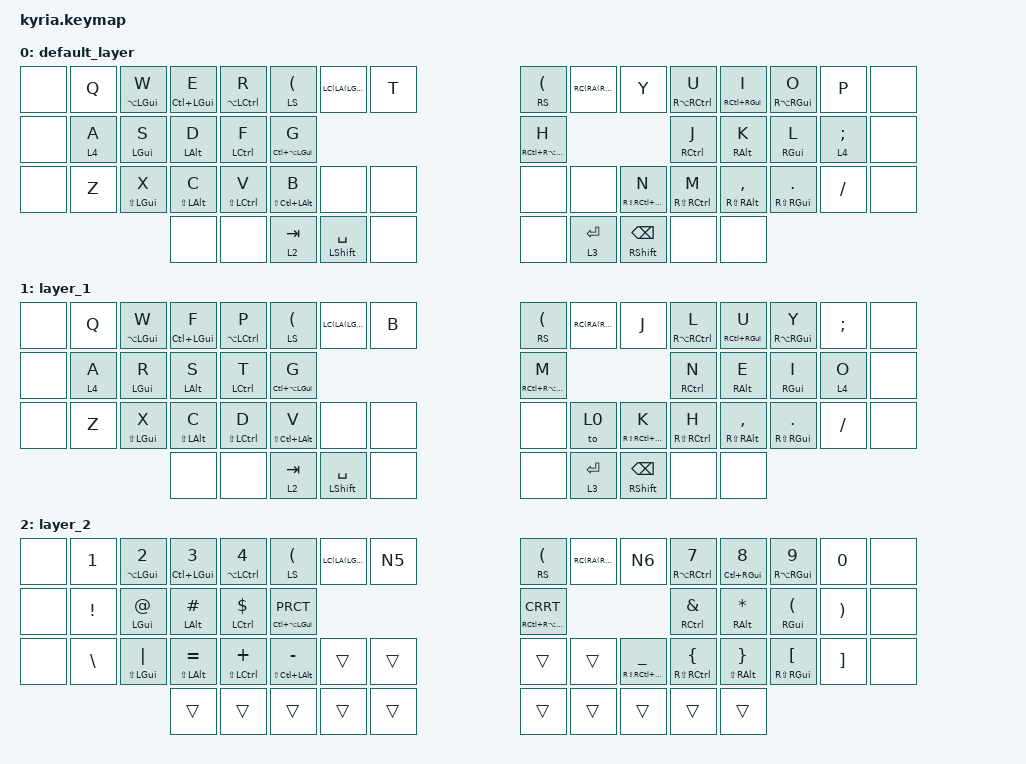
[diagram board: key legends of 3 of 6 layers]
/*
 * Copyright (c) 2020 The ZMK Contributors
 *
 * SPDX-License-Identifier: MIT
 */

#include <behaviors.dtsi>
#include <dt-bindings/zmk/keys.h>
#include <dt-bindings/zmk/outputs.h>
#include <dt-bindings/zmk/bt.h>

/ {
    behaviors {
        hm: homerow_mods {
            compatible = "zmk,behavior-hold-tap";
            label = "HOMEROW_MODS";
            #binding-cells = <2>;
            tapping-term-ms = <300>;
            quick-tap-ms = <0>;
            flavor = "tap-preferred";
            bindings = <&kp>, <&kp>;
        };
        tm: thumb_mods {
            compatible = "zmk,behavior-hold-tap";
            label = "THUMB_MODS";
            #binding-cells = <2>;
            tapping-term-ms = <200>;    // <---[[moderate duration]]
            quick-tap-ms = <0>;
            flavor = "hold-preferred";
            bindings = <&kp>, <&kp>;
        };
    };

    keymap {
        compatible = "zmk,keymap";

        default_layer {
// ---------------------------------------------------------------------------------------------------------------------------------
// Hold keys: (mods are symetrical)
// |     |     | A-G | C-G | C-A |SCA-G|                          |     |     |     |     |     |     |
// |     | L4  |  G  |  A  |  C  | CAG |                          |     |     |     |     |     |     |
// |     |     | S-G | S-A | S-C | SCA |     |     |~~|     |     |     |     |     |     |     |     |
//                   |     |     | L2  | Shf |     |~~|     | L3  | Shf |     |     |     
// ---------------------------------------------------------------------------------------------------------------------------------
// |     |  Q  |  W  |  E  |  R  |  T  |                          |  Y  |  U  |  I  |  O  |  P  |     |
// |     |  A  |  S  |  D  |  F  |  G  |                          |  H  |  J  |  K  |  L  |  ;  |     |
// |     |  Z  |  X  |  C  |  V  |  B  |     |     |~~| L1  |     |  N  |  M  |  ,  |  .  |  /  |     |
//                   |     |     | TAB | SPC |     |~~|     | RET | BKS |     |     |
            bindings = <
    &none &kp Q   &hm LA(LGUI) W &hm LC(LGUI) E &hm LA(LCTRL) R &hm LS(LC(LA(LGUI))) T                                           &hm RS(RC(RA(RGUI))) Y &hm RA(RCTRL) U &hm RC(RGUI) I     &hm RA(RGUI) O   &kp P      &none
    &none &lt 4 A &hm    LGUI  S &hm    LALT  D &hm    LCTRL  F &hm LC(LA(LGUI)) G                                               &hm RC(RA(RGUI)) H     &hm    RCTRL  J &hm    RALT  K     &hm    RGUI  L   &lt 4 SEMI &none
    &none &kp Z   &hm LS(LGUI) X &hm LS(LALT) C &hm LS(LCTRL) V &hm LS(LC(LALT)) B     &none           &none     &none &none     &hm RS(RC(RALT)) N     &hm RS(RCTRL) M &hm RS(RALT) COMMA &hm RS(RGUI) DOT &kp FSLH   &none
                                 &none          &none           &lt 2 TAB              &tm LSHFT SPACE &none     &none &lt 3 RET &tm RSHFT BKSP         &none           &none
            >;

            sensor-bindings = <&inc_dec_kp C_VOL_DN C_VOL_UP &inc_dec_kp LEFT RIGHT>;
        };

        layer_1 {
// ---------------------------------------------------------------------------------------------------------------------------------
// Hold keys: Same as above
// ---------------------------------------------------------------------------------------------------------------------------------
// Tap keys for Colemak
// |     |  Q  |  W  |  F  |  P  |  B  |                          |  J  |  L  |  U  |  Y  |  ;  |     |
// |     |  A  |  R  |  S  |  T  |  G  |                          |  M  |  N  |  E  |  I  |  O  |     |
// |     |  Z  |  X  |  C  |  D  |  V  |     |     |~~|     | L0  |  K  |  H  |  ,  |  .  |  /  |     |
//                   |     |     | TAB | SPC |     |~~|     | RET | BKS |     |     |
            bindings = <
    &none &kp Q   &hm LA(LGUI) W &hm LC(LGUI) F &hm LA(LCTRL) P &hm LS(LC(LA(LGUI))) B                                           &hm RS(RC(RA(RGUI))) J &hm RA(RCTRL) L &hm RC(RGUI) U     &hm RA(RGUI) Y   &kp SEMI  &none
    &none &lt 4 A &hm    LGUI  R &hm    LALT  S &hm    LCTRL  T &hm LC(LA(LGUI)) G                                               &hm RC(RA(RGUI)) M     &hm    RCTRL  N &hm    RALT  E     &hm    RGUI  I   &lt 4 O   &none
    &none &kp Z   &hm LS(LGUI) X &hm LS(LALT) C &hm LS(LCTRL) D &hm LS(LC(LALT)) V     &none           &none     &none &to 0     &hm RS(RC(RALT)) K     &hm RS(RCTRL) H &hm RS(RALT) COMMA &hm RS(RGUI) DOT &kp FSLH  &none
                                 &none          &none           &lt 2 TAB              &tm LSHFT SPACE &none     &none &lt 3 RET &tm RSHFT BKSP         &none           &none
            >;

            sensor-bindings = <&inc_dec_kp C_VOL_DN C_VOL_UP &inc_dec_kp LEFT RIGHT>;
        };

        layer_2 {
// ---------------------------------------------------------------------------------------------------------------------------------
// |     |  1  |  2  |  3  |  4  |  5  |                           |  6  |  7  |  8  |  9  |  0   |     |
// |     |  !  |  @  |  #  |  $  |  %  |                           |  ^  |  &  |  *  |  (  |  )   |     |
// |     |  \  |  |  |  =  |  +  |  -  |     |     |~~|     |      |  _  |  {  |  }  |  [  |  ]   |     |
//                   |     |     |     |     |     |~~|     |      |     |     |     |
            bindings = <
    &none &kp N1   &hm LA(LGUI) N2   &hm LC(LGUI) N3   &hm LA(LCTRL) N4   &hm LS(LC(LA(LGUI))) N5                                &hm RS(RC(RA(RGUI))) N6 &hm RA(RCTRL) N7   &hm LC(RGUI) N8   &hm RA(RGUI) N9   &kp N0   &none
    &none &kp EXCL &hm    LGUI  AT   &hm    LALT  HASH &hm    LCTRL  DLLR &hm LC(LA(LGUI)) PRCT                                  &hm RC(RA(RGUI)) CRRT   &hm    RCTRL  AMPS &hm    RALT  STAR &hm    RGUI  LPAR &kp RPAR &none
    &none &kp BSLH &hm LS(LGUI) PIPE &hm LS(LALT) EQL  &hm LS(LCTRL) PLUS &hm LS(LC(LALT)) MINUS  &trans &trans    &trans &trans &hm RS(RC(RALT)) UNDER  &hm RS(RCTRL) LBRC &hm LS(RALT) RBRC &hm RS(RGUI) LBKT &kp RBKT &none
                                     &trans            &trans             &trans                  &trans &trans    &trans &trans &trans                  &trans             &trans
            >;

            sensor-bindings = <&inc_dec_kp C_PREV C_NEXT &inc_dec_kp PG_UP PG_DN>;
        };

        layer_3 {
// QWERT is going to layer 0 for qerty
// COLMK is going to layer 1 for colemak
// 
// Note: Layer 3 doesn't have homerow mods on the right hand side, and some home row mods combos aren't available on the left.
//       This is intentional, at least for the movement and bks/del keys, this way they can be repeated by holding them.
// ---------------------------------------------------------------------------------------------------------------------------------
// |     |QWERT|COLMK|     |     |BT/USB|                         |     |  ~  | BKS | DEL |  `  |     |
// |     |     |     |     |     |     |                          |LEFT |DOWN | UP  |RIGHT|  '  |     |
// |     |     |     |     |     |     |     |     |  |     |     |HOME |P-DW |P-UP | END |  "  |     |
//                   |     |     |     |     |     |  |     |     |     |     |     |
            bindings = <
    &trans &to 0  &to 1  &trans &trans &out OUT_TOG                                &none    &kp TILD  &kp BKSP  &kp DEL   &kp GRAV &trans
    &trans &trans &trans &trans &trans &trans                                      &kp LEFT &kp DOWN  &kp UP    &kp RIGHT &kp SQT  &trans
    &trans &trans &trans &trans &trans &trans       &trans &trans    &trans &trans &kp HOME &kp PGDN  &kp PGUP  &kp END   &kp DQT  &trans
                         &trans &trans &trans       &trans &trans    &trans &trans &trans   &trans    &trans
            >;

            sensor-bindings = <&inc_dec_kp LC(LS(TAB)) LC(TAB) &inc_dec_kp PG_UP PG_DN>;
        };

        layer_4 {
// Note: Layer 4 doesn't have home row mods, but technically they could be added.
// ---------------------------------------------------------------------------------------------------------------------------------
// |     | F1  | F2  | F3  | F4  | F5  |                          | F6  | F7  | F8  | F9  | F10 |     |
// |     | FWD |NEXT |PLAY |VOL-U|MUTE |                          | F11 | F12 |     |     |     |     |
// |     | BWD |PREV |PAUSE|VOL-D|     |     |     |~~|     |     |     |     |     |     |     |     |
//                   |     |     |     |     | ESC |~~|     |     |     |     |     |
            bindings = <    
    &trans &kp F1   &kp F2     &kp F3      &kp F4   &kp F5                                     &kp F6  &kp F7  &kp F8 &kp F9 &kp F10 &trans
    &trans &kp C_FF &kp C_NEXT &kp C_PLAY  &kp VOLU &kp C_MUTE                                 &kp F11 &kp F12 &trans &trans &trans  &trans
    &trans &kp C_RW &kp C_PREV &kp C_PAUSE &kp VOLD &trans     &trans  &trans    &trans &trans &trans  &trans  &trans &trans &trans  &trans 
                               &trans      &trans   &trans     &kp ESC &trans    &trans &trans &trans  &trans  &trans
            >;

            sensor-bindings = <&inc_dec_kp LC(LS(TAB)) LC(TAB) &inc_dec_kp PG_UP PG_DN>;
        };

        layer_5 {
// ---------------------------------------------------------------------------------------------------------------------------------
// |     |     |     |     |     |     |                          |     |     |     |     |     |     |
// |     |     |     |     |     |     |                          |     |     |     |     |     |     |
// |     |     |     |     |     |     |     |     |~~|     |     |     |     |     |     |     |     |
//                   |     |     |     |     |     |~~|     |     |     |     |     |
            bindings = <
    &trans &trans &trans &trans &trans &trans                                &trans &trans &trans &trans  &trans  &none
    &trans &trans &trans &trans &trans &trans                                &trans &trans &trans &trans  &trans  &none
    &trans &trans &trans &trans &trans &trans &trans &trans    &trans &trans &trans &trans &trans &trans  &trans  &none
                                &trans &trans &trans &trans    &trans &trans &trans &trans &trans
            >;

            sensor-bindings = <&inc_dec_kp LC(LS(TAB)) LC(TAB) &inc_dec_kp PG_UP PG_DN>;
        };

    };
};

&left_encoder {
    resolution = <2>;
};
